# f280015x_dev_cfg_regs register map
Vendor: Texas Instruments
Peripheral module from a debugger description file (folder C2000).
Address unit: 16 bits
Registers are 32-bit, read-write, no defined reset value unless marked. A register's access mark holds for its fields unless they carry their own. Offsets are as the file gives them; lines under a group give offsets from that group; [hi:lo] are bit positions; {n}, {i} and the like mark numbered series; 'fields as' and 'values as' point back to an identical list; <NAME> marks a mode.

## DEV_CFG_REGS — DEV CFG Registers
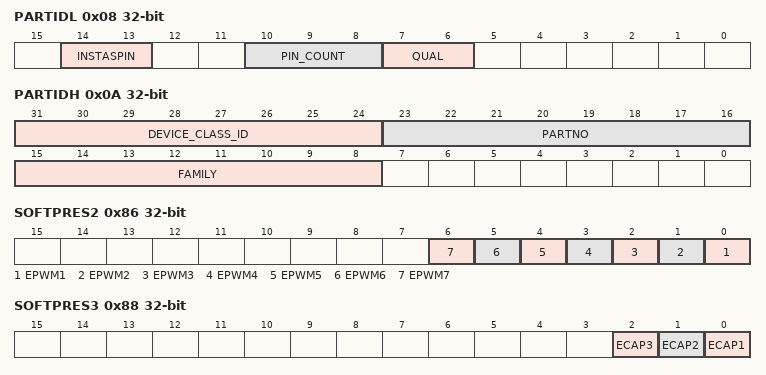
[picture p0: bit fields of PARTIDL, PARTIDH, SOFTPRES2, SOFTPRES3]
0x08 PARTIDL — Lower 32-bit of Device PART Identification Number
  [14:13] INSTASPIN — Instaspin feature set
  [10:8] PIN_COUNT — Device Pin Count
  [7:6] QUAL — Qualification Status
0x0A PARTIDH access per field — Upper 32-bit of Device PART Identification Number
  [31:24] DEVICE_CLASS_ID ro
  [23:16] PARTNO rw — Device part number
  [15:8] FAMILY rw — Device family
0x0C REVID — Device Revision Number
  [15:0] REVID — Device Revision ID. This is specific to the Device
0x74 TRIMERRSTS — TRIM Error Status register
  [15:0] LERR — TRIM Load error status
0x86 SOFTPRES2 — EPWM Software Reset register
  [n-1] EPWM{n} (n=1..7) — EPWM{n} software reset bit
0x88 SOFTPRES3 — ECAP Software Reset register
  [2] ECAP3 — ECAP3 software reset bit
  [1] ECAP2 — ECAP2 software reset bit
  [0] ECAP1 — ECAP1 software reset bit
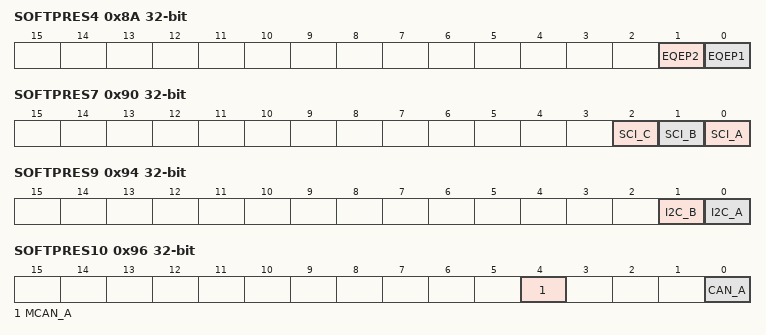
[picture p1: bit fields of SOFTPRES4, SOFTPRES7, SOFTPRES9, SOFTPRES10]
0x8A SOFTPRES4 — EQEP Software Reset register
  [1] EQEP2 — EQEP2 software reset bit
  [0] EQEP1 — EQEP1 software reset bit
0x90 SOFTPRES7 — SCI Software Reset register
  [2] SCI_C — SCI_C software reset bit
  [1] SCI_B — SCI_B software reset bit
  [0] SCI_A — SCI_A software reset bit
0x92 SOFTPRES8 — SPI Software Reset register
  [0] SPI_A — SPI_A software reset bit
0x94 SOFTPRES9 — I2C Software Reset register
  [1] I2C_B — I2C_B software reset bit
  [0] I2C_A — I2C_A software reset bit
0x96 SOFTPRES10 — CAN Software Reset register
  [4] MCAN_A — MCAN_A software reset bit
  [0] CAN_A — CAN_A software reset bit
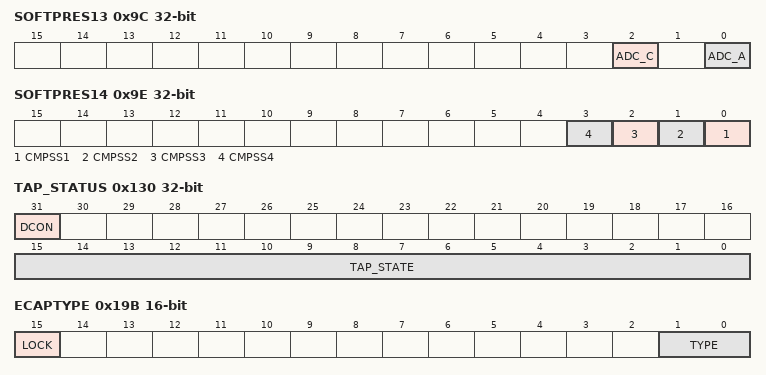
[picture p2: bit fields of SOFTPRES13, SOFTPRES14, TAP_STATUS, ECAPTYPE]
0x9C SOFTPRES13 — ADC Software Reset register
  [2] ADC_C — ADC_C software reset bit
  [0] ADC_A — ADC_A software reset bit
0x9E SOFTPRES14 — CMPSS Software Reset register
  [n-1] CMPSS{n} (n=1..4) — CMPSS{n} software reset bit
0xA8 SOFTPRES19 — LIN Software Reset register
  [0] LIN_A — LIN_A software reset bit
0xAA SOFTPRES20 — PMBUS Software Reset register
  [0] PMBUS_A — PMBUS_A software reset bit
0xAC SOFTPRES21 — DCC Software Reset register
  [0] DCC0 — DCC Module reset bit
0xB8 SOFTPRES27 — EPG Software Reset register
  [0] EPG1 — EPG Module Reset Bit
0xBA SOFTPRES28 — Flash Software Reset register
  [0] FLASHA — Flash Wrapper Module Reset Bit
0x130 TAP_STATUS ro — Status of JTAG State machine and Debugger Connect
  [31] DCON — Debugger Connect Indication
  [15:0] TAP_STATE — Present TAP State
0x19B ECAPTYPE 16-bit — Configures ECAP Type for the device
  [15] LOCK — Lock bit for the register
  [1:0] TYPE — Configure ECAP type
